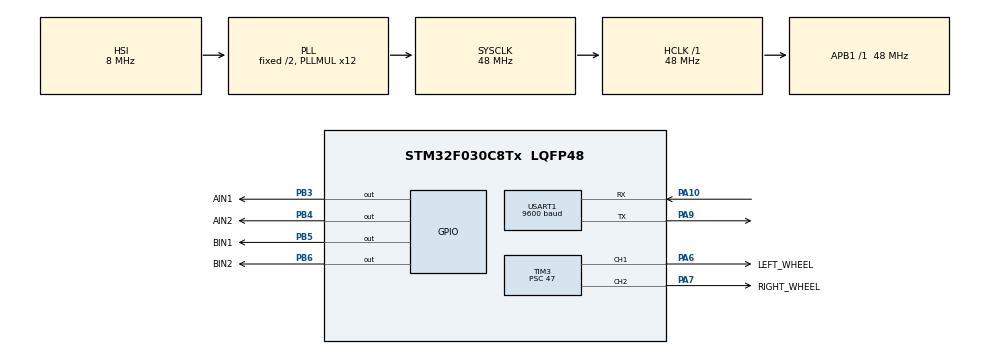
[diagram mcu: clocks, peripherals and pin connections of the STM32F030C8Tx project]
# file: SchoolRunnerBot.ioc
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Mcu.Family=STM32F0
Mcu.Name=STM32F030C8Tx
Mcu.Package=LQFP48
NVIC.USART1_IRQn=true\:2\:0\:true\:false\:true\:true\:true\:true
PA10.Mode=Asynchronous
PA10.Signal=USART1_RX
PA6.GPIO_Label=LEFT_WHEEL
PA6.Signal=S_TIM3_CH1
PA7.GPIO_Label=RIGHT_WHEEL
PA7.Signal=S_TIM3_CH2
PA9.Mode=Asynchronous
PA9.Signal=USART1_TX
PB3.GPIO_Label=AIN1
PB3.Signal=GPIO_Output
PB4.GPIO_Label=AIN2
PB4.Signal=GPIO_Output
PB5.GPIO_Label=BIN1
PB5.Signal=GPIO_Output
PB6.GPIO_Label=BIN2
PB6.Signal=GPIO_Output
PF0-OSC_IN.Mode=HSE-External-Oscillator
PF0-OSC_IN.Signal=RCC_OSC_IN
PF1-OSC_OUT.Mode=HSE-External-Oscillator
PF1-OSC_OUT.Signal=RCC_OSC_OUT
ProjectManager.HeapSize=0x200
ProjectManager.StackSize=0x400
ProjectManager.TargetToolchain=MDK-ARM V5.32
RCC.AHBFreq_Value=48000000
RCC.APB1Freq_Value=48000000
RCC.APB1TimFreq_Value=48000000
RCC.HCLKFreq_Value=48000000
RCC.PLLMUL=RCC_PLL_MUL12
RCC.SYSCLKFreq_VALUE=48000000
RCC.SYSCLKSource=RCC_SYSCLKSOURCE_PLLCLK
SH.S_TIM3_CH1.0=TIM3_CH1,PWM Generation1 CH1
SH.S_TIM3_CH2.0=TIM3_CH2,PWM Generation2 CH2
TIM3.Channel-PWM\ Generation1\ CH1=TIM_CHANNEL_1
TIM3.Channel-PWM\ Generation2\ CH2=TIM_CHANNEL_2
TIM3.Period=99
TIM3.Prescaler=47
USART1.BaudRate=9600
USART1.VirtualMode-Asynchronous=VM_ASYNC
board=custom

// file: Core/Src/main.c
/* USER CODE BEGIN Header */
/**
  ******************************************************************************
  * @file           : main.c
  * @brief          : Main program body
  ******************************************************************************
  * @attention
  *
  * Copyright (c) 2024 STMicroelectronics.
  * All rights reserved.
  *
  * This software is licensed under terms that can be found in the LICENSE file
  * in the root directory of this software component.
  * If no LICENSE file comes with this software, it is provided AS-IS.
  *
  ******************************************************************************
  */
/* USER CODE END Header */
#include "main.h"
#include "tim.h"
#include "usart.h"
#include "gpio.h"

/* USER CODE BEGIN Includes */
#include "CommandType.h"
#include "BlueTooth.h"
/* USER CODE END Includes */

/* USER CODE BEGIN PV */
uint8_t DataReceiveCache;
uint8_t DataReceive;

Queue RxQueue;
Queue_Pointer RxQueue_Pointer;

uint8_t ComData;
/* USER CODE END PV */

void SystemClock_Config(void);

int main(void)
{

  /* MCU Configuration--------------------------------------------------------*/

  /* Reset of all peripherals, Initializes the Flash interface and the Systick. */
  HAL_Init();

  /* Configure the system clock */
  SystemClock_Config();

  /* Initialize all configured peripherals */
  MX_GPIO_Init();
  MX_TIM3_Init();
  MX_USART1_UART_Init();
  /* USER CODE BEGIN 2 */
  BluetoothInit(BLUETOOTH_PORT);
  /* USER CODE END 2 */

  /* Infinite loop */
  while (1)
  {

    /* USER CODE BEGIN 3 */
    if(RxQueue_Pointer.END->data=='E')
    {
      CommandDecode(&RxQueue_Pointer);
    }
    else
      HAL_Delay(50);
  }
  /* USER CODE END 3 */
}

void SystemClock_Config(void)
{
  RCC_OscInitTypeDef RCC_OscInitStruct = {0};
  RCC_ClkInitTypeDef RCC_ClkInitStruct = {0};
  RCC_PeriphCLKInitTypeDef PeriphClkInit = {0};

  /** Initializes the RCC Oscillators according to the specified parameters
  * in the RCC_OscInitTypeDef structure.
  */
  RCC_OscInitStruct.OscillatorType = RCC_OSCILLATORTYPE_HSI;
  RCC_OscInitStruct.HSIState = RCC_HSI_ON;
  RCC_OscInitStruct.HSICalibrationValue = RCC_HSICALIBRATION_DEFAULT;
  RCC_OscInitStruct.PLL.PLLState = RCC_PLL_ON;
  RCC_OscInitStruct.PLL.PLLSource = RCC_PLLSOURCE_HSI;
  RCC_OscInitStruct.PLL.PLLMUL = RCC_PLL_MUL12;
  RCC_OscInitStruct.PLL.PREDIV = RCC_PREDIV_DIV1;
  if (HAL_RCC_OscConfig(&RCC_OscInitStruct) != HAL_OK)
  {
    Error_Handler();
  }

  /** Initializes the CPU, AHB and APB buses clocks
  */
  RCC_ClkInitStruct.ClockType = RCC_CLOCKTYPE_HCLK|RCC_CLOCKTYPE_SYSCLK
                              |RCC_CLOCKTYPE_PCLK1;
  RCC_ClkInitStruct.SYSCLKSource = RCC_SYSCLKSOURCE_PLLCLK;
  RCC_ClkInitStruct.AHBCLKDivider = RCC_SYSCLK_DIV1;
  RCC_ClkInitStruct.APB1CLKDivider = RCC_HCLK_DIV1;

  if (HAL_RCC_ClockConfig(&RCC_ClkInitStruct, FLASH_LATENCY_1) != HAL_OK)
  {
    Error_Handler();
  }
  PeriphClkInit.PeriphClockSelection = RCC_PERIPHCLK_USART1;
  PeriphClkInit.Usart1ClockSelection = RCC_USART1CLKSOURCE_PCLK1;
  if (HAL_RCCEx_PeriphCLKConfig(&PeriphClkInit) != HAL_OK)
  {
    Error_Handler();
  }
}

void Error_Handler(void)
{
  __disable_irq();
  while (1)
  {
  }
}
